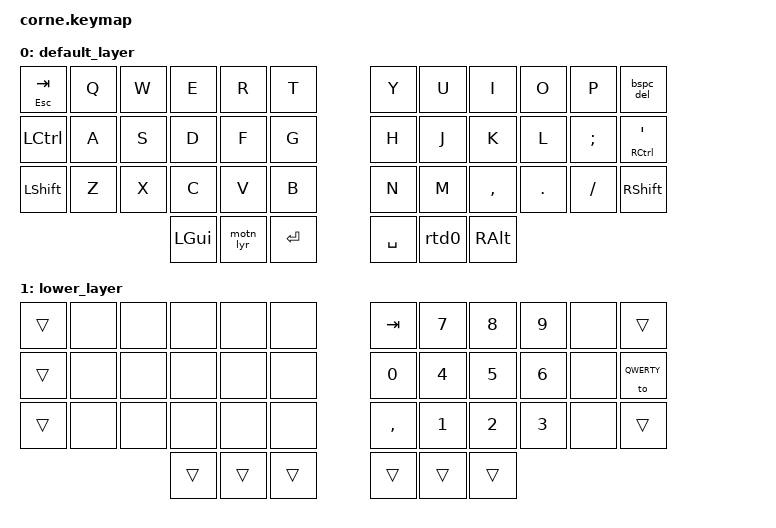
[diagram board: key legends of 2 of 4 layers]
/*
 * Copyright (c) 2020 The ZMK Contributors
 *
 * SPDX-License-Identifier: MIT
 */

//Box Making Characters 
//┌ ┬ ┐ 

//├ ┼ ┤ │  ─ 

//└ ┴ ┘

/* TODO:
*Add bluetooth profile Macro
*Finish bluetooth profile implementation
*General clean up
*/

#include <behaviors.dtsi>
#include <dt-bindings/zmk/keys.h>
#include <dt-bindings/zmk/bt.h>

//Layer Defines
#define QWERTY  0
#define NUM     1
#define SYMB    2
#define MOTION  3
#define MEDIA   4

// Mouse keys
#include <dt-bindings/zmk/pointing.h>
#define ZMK_POINTING_DEFAULT_MOVE_VAL 700  // default: 600
#define ZMK_POINTING_DEFAULT_SCRL_VAL 10    // default: 10

//Mouse Abreviations
#define MVLFT MOVE_LEFT
#define MVDWN MOVE_DOWN
#define MVUP  MOVE_UP
#define MVRGT MOVE_RIGHT


//Bluetooth keys
#define _BT_HOLD_TO_ACTIVATE_ &bth BT_SEL 0  &bth BT_SEL 1   &bth BT_SEL 2   &bth BT_SEL 3 


/ {
//  macros {
//      bt_sel_mac: bt_sel_mac {
//          compatible = "zmk,behavior-macro-one-param";
//          #binding-cells = <1>;
//          bindings
//              = <&macro_param_1to1>
//      	, <&macro_tap &bt BT_SEL MACRO_PLACEHOLDER>
//              ;
//      };
//  };


    behaviors {
        ltd0: tap_dance_0 {
            compatible = "zmk,behavior-tap-dance";
            #binding-cells = <0>;
            tapping-term-ms = <200>;
            bindings = <&mo NUM>, <&tog SYMB>;
        };
        rtd0: tap_dance_1 {
            compatible = "zmk,behavior-tap-dance";
            #binding-cells = <0>;
            tapping-term-ms = <200>;
            bindings = <&mo SYMB>, <&tog NUM>;
        };
        bth: hold_to_change_bt {
            compatible = "zmk,behavior-hold-tap";
            #binding-cells = <2>;
            flavor = "hold-preferred";
            tapping-term-ms = <3000>;
            bindings = <&bt>, <&none>;
            display-name = "hold-to-change-bt";
        };
        bspc_del: backspace_delete {
            compatible = "zmk,behavior-mod-morph";
            #binding-cells = <0>;
            bindings = <&kp BACKSPACE>, <&kp DELETE>;
            mods = <(MOD_LSFT)>;
        };
        motn_lyr: motion_layer {
            compatible = "zmk,behavior-mod-morph";
            #binding-cells = <0>;
            bindings = <&ltd0>, <&mo MOTION>;
            mods = <(MOD_LSFT)>;
        };
    };





        keymap {
                compatible = "zmk,keymap";

                default_layer {
                        bindings = <
// ┌───────────┬──────────┬──────────┬──────────┬──────────┬──────────┐            ┌──────────┬──────────┬──────────┬──────────┬──────────┬──────────┐
// │ TAB/ESC   │   Q      │   W      │   E      │   R      │   T      │            │   Y      │   U      │   I      │   O      │   P      │  BSPC    │
    &mt ESC TAB  &kp Q     &kp W       &kp E      &kp R      &kp T                   &kp Y      &kp U      &kp I      &kp O     &kp P      &bspc_del 
// ├───────────┬──────────┼──────────┼──────────┼──────────┼──────────┤            ├──────────┼──────────┼──────────┼──────────┼──────────┼──────────┤
// │   CTRL    │   A      │   S      │   D      │   F      │  G       │            │   H      │   J      │   K      │   L      │   ;      │ ' / RCTL │
     &kp LCTRL    &kp A      &kp S      &kp D      &kp F     &kp G                   &kp H       &kp J      &kp K      &kp L     &kp SEMI  &mt RCTL SQT
// ├───────────┼──────────┼──────────┼──────────┼──────────┼──────────┤            ├──────────┼──────────┼──────────┼──────────┼──────────┼──────────┤
// │  SHFT     │  Z       │  X       │  C       │  V       │  B       │            │   N      │  M       │  ,       │  .       │  /       │ SHFT     │
     &kp LSHFT   &kp Z      &kp X      &kp C      &kp V      &kp B                    &kp N     &kp M      &kp COMMA  &kp DOT    &kp FSLH   &kp RSHFT
// └───────────┴──────────┴──────────┼──────────┼──────────┼──────────┤            ├──────────┼──────────┼──────────┼──────────┴──────────┴──────────┘
//                                   │  GUI     │ L LYRCTL │  ENT     │            │  SPC     │ R LYRCTL │  ALT     │
                                       &kp LGUI  &motn_lyr    &kp RET                &kp SPACE   &rtd0     &kp RALT
//                                   └──────────┴──────────┴──────────┘            └──────────┴──────────┴──────────┘
                        >;
                };
                lower_layer {
                        bindings = <
//┌───────────┬──────────┬──────────┬──────────┬──────────┬──────────┐             ┌──────────┬──────────┬──────────┬──────────┬──────────┬──────────┐
//│           │          │          │          │          │          │             │  TAB     │  7 / &   │  8 / *   │  9 / (   │          │          │
      &trans     &none      &none      &none      &none      &none                   &kp TAB     &kp N7     &kp N8     &kp N9     &none      &trans
//├───────────┬──────────┼──────────┼──────────┼──────────┼──────────┤             ├──────────┼──────────┼──────────┼──────────┼──────────┼──────────┤
//│           │          │          │          │          │          │             │  0 / )   │  4 / $   │  5 / %   │  6 / ^   │          │          │
      &trans     &none      &none      &none      &none      &none                    &kp N0     &kp N4     &kp N5     &kp N6     &none    &to QWERTY
//├───────────┼──────────┼──────────┼──────────┼──────────┼──────────┤             ├──────────┼──────────┼──────────┼──────────┼──────────┼──────────┤
//│                                                                  │             │     ,    │  1 / !   │  2 / @   │  3 / #   │          │          │
      &trans     &none      &none      &none      &none      &none                  &kp COMMA    &kp N1     &kp N2     &kp N3     &none      &trans   
//└───────────┴──────────┴──────────┼──────────┼──────────┼──────────┤             ├──────────┼──────────┼──────────┼──────────┴──────────┴──────────┘
//                                  │          │          │          │             │          │          │          │
                                      &trans      &trans     &trans                   &trans     &trans     &trans
//                                  └──────────┴──────────┴──────────┘             └──────────┴──────────┴──────────┘
                        >;
                };
                raise_layer {
                        bindings = <
//┌───────────┬──────────┬──────────┬──────────┬──────────┬──────────┐             ┌──────────┬──────────┬──────────┬──────────┬──────────┬──────────┐
//│           │   ` / ~  │   [      │   ]      │    |     │   = / +  │             │ MSMV_LFT │ MSMV_DWN │ MSMV_UP  │ MSMV_RGT │          │          │
     &trans    &kp GRAVE   &kp LBKT   &kp RBKT   &kp PIPE  &kp EQUAL                &mmv MVLFT &mmv MVDWN &mmv MVUP  &mmv MVRGT   &none      &trans
//├───────────┬──────────┼──────────┼──────────┼──────────┼──────────┤             ├──────────┼──────────┼──────────┼──────────┼──────────┼──────────┤
//│           │          │   (      │    )     │  \ / |   │  - / _   │             │   LFT    │   DWN    │   UP     │   RGT    │  MDLCLK  │          │
     &trans      &none     &kp LPAR   &kp RPAR   &kp BSLH  &kp MINUS                 &kp LEFT   &kp DOWN   &kp UP    &kp RIGHT  &mkp MCLK    &trans
//├───────────┼──────────┼──────────┼──────────┼──────────┼──────────┤             ├──────────┼──────────┼──────────┼──────────┼──────────┼──────────┤
//│           │          │   {      │    }     │ "/" / ?  │          │             │ BT CLEAR │  BTP 0   │  BTP 1   │  BTP 2   │  BTP 3   │          │
     &trans      &none     &kp LBRC   &kp RBRC   &kp FSLH    &none                  &bth BT_CLR           _BT_HOLD_TO_ACTIVATE_              &trans
//└───────────┴──────────┴──────────┼──────────┼──────────┼──────────┤             ├──────────┼──────────┼──────────┼──────────┴──────────┴──────────┘
//                                  │          │          │          │             │ LFTCLK   │          │  RGTCLK  │
                                      &trans      &trans     &trans                 &mkp LCLK    &trans    &mkp RCLK
//                                  └──────────┴──────────┴──────────┘             └──────────┴──────────┴──────────┘
                        >;
                };
                motion_layer {
                        bindings = <
//┌───────────┬──────────┬──────────┬──────────┬──────────┬──────────┐             ┌──────────┬──────────┬──────────┬──────────┬──────────┬──────────┐
//│           │   ` / ~  │   [      │   ]      │    |     │   = / +  │             │ MSMV_LFT │ MSMV_DWN │ MSMV_UP  │ MSMV_RGT │          │          │
     &trans    &kp GRAVE   &kp LBKT   &kp RBKT   &kp PIPE  &kp EQUAL                &mmv MVLFT &mmv MVDWN &mmv MVUP  &mmv MVRGT   &none      &trans
//├───────────┬──────────┼──────────┼──────────┼──────────┼──────────┤             ├──────────┼──────────┼──────────┼──────────┼──────────┼──────────┤
//│           │          │   (      │    )     │  \ / |   │  - / _   │             │   LFT    │   DWN    │   UP     │   RGT    │    END   │          │
     &trans      &none     &kp LPAR   &kp RPAR   &kp BSLH  &kp MINUS                 &kp LEFT   &kp DOWN   &kp UP    &kp RIGHT   &kp END     &trans
//├───────────┼──────────┼──────────┼──────────┼──────────┼──────────┤             ├──────────┼──────────┼──────────┼──────────┼──────────┼──────────┤
//│           │          │   {      │    }     │ "/" / ?  │          │             │ BT CLEAR │  BTP 0   │  BTP 1   │  BTP 2   │  BTP 3   │          │
     &trans      &none     &kp LBRC   &kp RBRC   &kp FSLH    &none                  &bth BT_CLR           _BT_HOLD_TO_ACTIVATE_              &trans
//└───────────┴──────────┴──────────┼──────────┼──────────┼──────────┤             ├──────────┼──────────┼──────────┼──────────┴──────────┴──────────┘
//                                  │          │          │          │             │ LFTCLK   │          │  RGTCLK  │
                                      &trans      &trans     &trans                 &mkp LCLK    &trans    &mkp RCLK
//                                  └──────────┴──────────┴──────────┘             └──────────┴──────────┴──────────┘
                        >;
                };
        };
};
